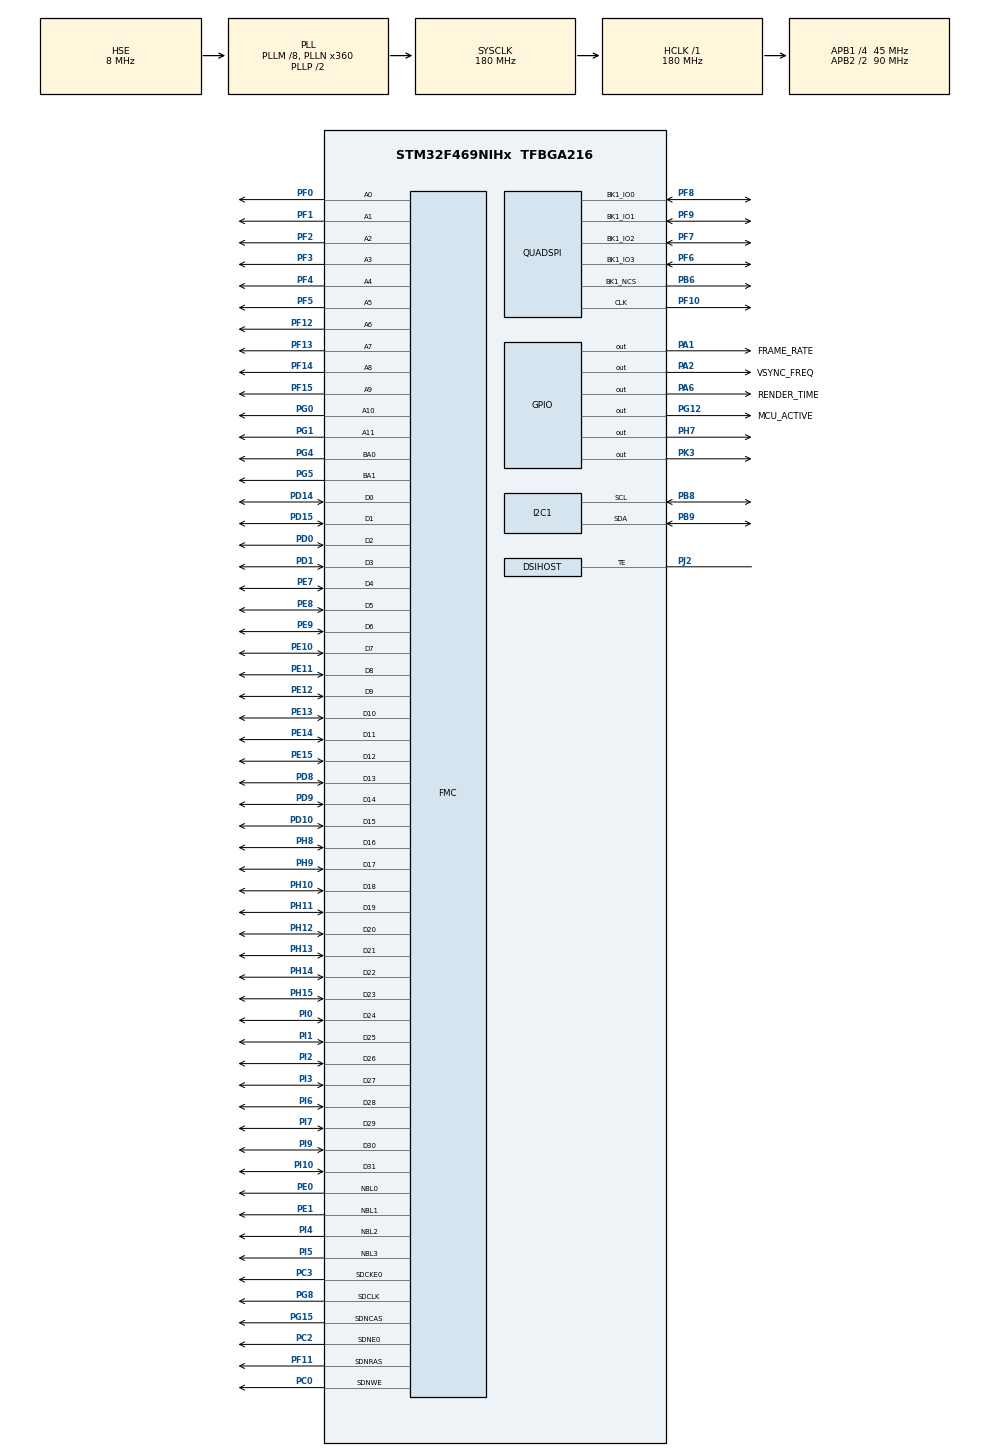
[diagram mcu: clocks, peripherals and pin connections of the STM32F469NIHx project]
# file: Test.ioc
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DMA2D.ColorMode=DMA2D_OUTPUT_ARGB8888
DSIHOST.AcknowledgeRequest=DSI_ACKNOWLEDGE_ENABLE
DSIHOST.AutomaticRefresh=DSI_AR_DISABLE
DSIHOST.CommandSize=200
DSIHOST.LPDcsLongWrite=DSI_LP_DLW_ENABLE
DSIHOST.LPDcsShortReadNoP=DSI_LP_DSR0P_ENABLE
DSIHOST.LPDcsShortWriteNoP=DSI_LP_DSW0P_ENABLE
DSIHOST.LPDcsShortWriteOneP=DSI_LP_DSW1P_ENABLE
DSIHOST.LPGenLongWrite=DSI_LP_GLW_ENABLE
DSIHOST.LPGenShortReadNoP=DSI_LP_GSR0P_ENABLE
DSIHOST.LPGenShortReadOneP=DSI_LP_GSR1P_ENABLE
DSIHOST.LPGenShortReadTwoP=DSI_LP_GSR2P_ENABLE
DSIHOST.LPGenShortWriteNoP=DSI_LP_GSW0P_ENABLE
DSIHOST.LPGenShortWriteOneP=DSI_LP_GSW1P_ENABLE
DSIHOST.LPGenShortWriteTwoP=DSI_LP_GSW2P_ENABLE
DSIHOST.LPMaxReadPacket=DSI_LP_MRDP_ENABLE
DSIHOST.NumberOfLanes=DSI_TWO_DATA_LANES
DSIHOST.TEAcknowledgeRequest=DSI_TE_ACKNOWLEDGE_ENABLE
DSIHOST.TimeoutCkdiv=1
DSIHOST_CKN.Mode=DSIHost_Adapted_TE
DSIHOST_CKN.Signal=DSIHOST_CKN
DSIHOST_CKP.Mode=DSIHost_Adapted_TE
DSIHOST_CKP.Signal=DSIHOST_CKP
DSIHOST_D0N.Mode=DSIHost_Adapted_TE
DSIHOST_D0N.Signal=DSIHOST_D0N
DSIHOST_D0P.Mode=DSIHost_Adapted_TE
DSIHOST_D0P.Signal=DSIHOST_D0P
DSIHOST_D1N.Mode=DSIHost_Adapted_TE
DSIHOST_D1N.Signal=DSIHOST_D1N
DSIHOST_D1P.Mode=DSIHost_Adapted_TE
DSIHOST_D1P.Signal=DSIHOST_D1P
FMC.CASLatency1=FMC_SDRAM_CAS_LATENCY_3
FMC.ExitSelfRefreshDelay1=7
FMC.LoadToActiveDelay1=2
FMC.RCDDelay1=2
FMC.RPDelay1=2
FMC.ReadBurst1=FMC_SDRAM_RBURST_ENABLE
FMC.ReadPipeDelay1=FMC_SDRAM_RPIPE_DELAY_2
FMC.RowCycleDelay1=7
FMC.SelfRefreshTime1=4
FMC.WriteRecoveryTime1=3
FREERTOS.Tasks01=defaultTask,24,128,StartDefaultTask,Default,NULL,Dynamic,NULL,NULL;TouchGFXTask,24,4096,TouchGFX_Task,As external,NULL,Dynamic,NULL,NULL;readAdcTaskName,48,128,readAdcFunction,As external,NULL,Dynamic,NULL,NULL
FREERTOS.configTOTAL_HEAP_SIZE=32768
FREERTOS.configUSE_APPLICATION_TASK_TAG=1
FREERTOS.configUSE_IDLE_HOOK=1
FREERTOS.configUSE_NEWLIB_REENTRANT=1
FREERTOS.configUSE_TRACE_FACILITY=1
I2C1.I2C_Mode=I2C_Fast
LTDC.ActiveW=200
LTDC.Alpha_L0=255
LTDC.FBStartAdress_L0=0xC0000000
LTDC.HBP=1
LTDC.HFP=1
LTDC.HSync=2
LTDC.ImageHeight_L0=480
LTDC.ImageWidth_L0=200
LTDC.Layers=0
LTDC.PixelFormat_L0=LTDC_PIXEL_FORMAT_RGB565
LTDC.VBP=1
LTDC.VFP=1
LTDC.VSync=2
LTDC.WindowX1_L0=200
LTDC.WindowY1_L0=480
Mcu.Family=STM32F4
Mcu.Name=STM32F469NIHx
Mcu.Package=TFBGA216
NVIC.DMA2D_IRQn=true\:5\:0\:true\:false\:true\:false\:true\:true\:true
NVIC.DSI_IRQn=true\:5\:0\:true\:false\:true\:false\:true\:true\:true
NVIC.LTDC_IRQn=true\:5\:0\:true\:false\:true\:false\:true\:true\:true
NVIC.PriorityGroup=NVIC_PRIORITYGROUP_4
NVIC.TIM6_DAC_IRQn=true\:0\:0\:false\:false\:true\:false\:false\:true\:true
NVIC.TimeBase=TIM6_DAC_IRQn
NVIC.TimeBaseIP=TIM6
PA1.GPIO_Label=FRAME_RATE
PA1.GPIO_Speed=GPIO_SPEED_FREQ_VERY_HIGH
PA1.Signal=GPIO_Output
PA2.GPIO_Label=VSYNC_FREQ
PA2.GPIO_Speed=GPIO_SPEED_FREQ_VERY_HIGH
PA2.Signal=GPIO_Output
PA6.GPIO_Label=RENDER_TIME
PA6.GPIO_Speed=GPIO_SPEED_FREQ_VERY_HIGH
PA6.Signal=GPIO_Output
PB6.Mode=Single Bank 1
PB6.Signal=QUADSPI_BK1_NCS
PB8.GPIO_Pu=GPIO_PULLUP
PB8.Mode=I2C
PB8.Signal=I2C1_SCL
PB9.GPIO_Pu=GPIO_PULLUP
PB9.Mode=I2C
PB9.Signal=I2C1_SDA
PC0.Signal=FMC_SDNWE
PC2.Mode=SdramChipSelect1_1
PC2.Signal=FMC_SDNE0
PC3.Mode=SdramChipSelect1_1
PC3.Signal=FMC_SDCKE0
PD0.Signal=FMC_D2_DA2
PD1.Signal=FMC_D3_DA3
PD10.Signal=FMC_D15_DA15
PD14.Signal=FMC_D0_DA0
PD15.Signal=FMC_D1_DA1
PD8.Signal=FMC_D13_DA13
PD9.Signal=FMC_D14_DA14
PE0.Signal=FMC_NBL0
PE1.Signal=FMC_NBL1
PE10.Signal=FMC_D7_DA7
PE11.Signal=FMC_D8_DA8
PE12.Signal=FMC_D9_DA9
PE13.Signal=FMC_D10_DA10
PE14.Signal=FMC_D11_DA11
PE15.Signal=FMC_D12_DA12
PE7.Signal=FMC_D4_DA4
PE8.Signal=FMC_D5_DA5
PE9.Signal=FMC_D6_DA6
PF0.Signal=FMC_A0
PF1.Signal=FMC_A1
PF10.Mode=Single Bank 1
PF10.Signal=QUADSPI_CLK
PF11.Signal=FMC_SDNRAS
PF12.Signal=FMC_A6
PF13.Signal=FMC_A7
PF14.Signal=FMC_A8
PF15.Signal=FMC_A9
PF2.Signal=FMC_A2
PF3.Signal=FMC_A3
PF4.Signal=FMC_A4
PF5.Signal=FMC_A5
PF6.Mode=Single Bank 1
PF6.Signal=QUADSPI_BK1_IO3
PF7.Mode=Single Bank 1
PF7.Signal=QUADSPI_BK1_IO2
PF8.Mode=Single Bank 1
PF8.Signal=QUADSPI_BK1_IO0
PF9.Mode=Single Bank 1
PF9.Signal=QUADSPI_BK1_IO1
PG0.Signal=FMC_A10
PG1.Signal=FMC_A11
PG12.GPIO_Label=MCU_ACTIVE
PG12.GPIO_Speed=GPIO_SPEED_FREQ_VERY_HIGH
PG12.Signal=GPIO_Output
PG15.Signal=FMC_SDNCAS
PG4.Signal=FMC_A14_BA0
PG5.Signal=FMC_A15_BA1
PG8.Signal=FMC_SDCLK
PH0/OSC_IN.Mode=HSE-External-Oscillator
PH0/OSC_IN.Signal=RCC_OSC_IN
PH1/OSC_OUT.Mode=HSE-External-Oscillator
PH1/OSC_OUT.Signal=RCC_OSC_OUT
PH10.Signal=FMC_D18
PH11.Signal=FMC_D19
PH12.Signal=FMC_D20
PH13.Signal=FMC_D21
PH14.Signal=FMC_D22
PH15.Signal=FMC_D23
PH7.GPIO_ModeDefaultOutputPP=GPIO_MODE_OUTPUT_OD
PH7.GPIO_Speed=GPIO_SPEED_FREQ_VERY_HIGH
PH7.PinState=GPIO_PIN_RESET
PH7.Signal=GPIO_Output
PH8.Signal=FMC_D16
PH9.Signal=FMC_D17
PI0.Signal=FMC_D24
PI1.Signal=FMC_D25
PI10.Signal=FMC_D31
PI2.Signal=FMC_D26
PI3.Signal=FMC_D27
PI4.Signal=FMC_NBL2
PI5.Signal=FMC_NBL3
PI6.Signal=FMC_D28
PI7.Signal=FMC_D29
PI9.Signal=FMC_D30
PJ2.Mode=DSIHost_Adapted_TE
PJ2.Signal=DSIHOST_TE
PK3.GPIO_ModeDefaultOutputPP=GPIO_MODE_OUTPUT_OD
PK3.PinState=GPIO_PIN_SET
PK3.Signal=GPIO_Output
ProjectManager.HeapSize=0x1000
ProjectManager.StackSize=0x1000
ProjectManager.TargetToolchain=STM32CubeIDE
QUADSPI.ChipSelectHighTime=QSPI_CS_HIGH_TIME_5_CYCLE
QUADSPI.ClockPrescaler=1
QUADSPI.FlashSize=27
QUADSPI.SampleShifting=QSPI_SAMPLE_SHIFTING_HALFCYCLE
RCC.AHBFreq_Value=180000000
RCC.APB1CLKDivider=RCC_HCLK_DIV4
RCC.APB1Freq_Value=45000000
RCC.APB1TimFreq_Value=90000000
RCC.APB2CLKDivider=RCC_HCLK_DIV2
RCC.APB2Freq_Value=90000000
RCC.APB2TimFreq_Value=180000000
RCC.CortexFreq_Value=180000000
RCC.HCLKFreq_Value=180000000
RCC.HSE_VALUE=8000000
RCC.PLLDSIIDF=DSI_PLL_IN_DIV2
RCC.PLLDSINDIV=125
RCC.PLLM=8
RCC.PLLN=360
RCC.PLLR=6
RCC.PLLSAIN=360
RCC.PLLSAIR=6
RCC.PLLSourceVirtual=RCC_PLLSOURCE_HSE
RCC.SYSCLKFreq_VALUE=180000000
RCC.SYSCLKSource=RCC_SYSCLKSOURCE_PLLCLK
RCC.USBFreq_Value=90000000
RCC.VCOOutputFreq_Value=360000000
SH.FMC_A0.0=FMC_A0,12b-sda1
SH.FMC_A1.0=FMC_A1,12b-sda1
SH.FMC_A10.0=FMC_A10,12b-sda1
SH.FMC_A11.0=FMC_A11,12b-sda1
SH.FMC_A14_BA0.0=FMC_BA0,FourSdramBanks1
SH.FMC_A15_BA1.0=FMC_BA1,FourSdramBanks1
SH.FMC_A2.0=FMC_A2,12b-sda1
SH.FMC_A3.0=FMC_A3,12b-sda1
SH.FMC_A4.0=FMC_A4,12b-sda1
SH.FMC_A5.0=FMC_A5,12b-sda1
SH.FMC_A6.0=FMC_A6,12b-sda1
SH.FMC_A7.0=FMC_A7,12b-sda1
SH.FMC_A8.0=FMC_A8,12b-sda1
SH.FMC_A9.0=FMC_A9,12b-sda1
SH.FMC_D0_DA0.0=FMC_D0,sd-32b-d1
SH.FMC_D10_DA10.0=FMC_D10,sd-32b-d1
SH.FMC_D11_DA11.0=FMC_D11,sd-32b-d1
SH.FMC_D12_DA12.0=FMC_D12,sd-32b-d1
SH.FMC_D13_DA13.0=FMC_D13,sd-32b-d1
SH.FMC_D14_DA14.0=FMC_D14,sd-32b-d1
SH.FMC_D15_DA15.0=FMC_D15,sd-32b-d1
SH.FMC_D16.0=FMC_D16,sd-32b-d1
SH.FMC_D17.0=FMC_D17,sd-32b-d1
SH.FMC_D18.0=FMC_D18,sd-32b-d1
SH.FMC_D19.0=FMC_D19,sd-32b-d1
SH.FMC_D1_DA1.0=FMC_D1,sd-32b-d1
SH.FMC_D20.0=FMC_D20,sd-32b-d1
SH.FMC_D21.0=FMC_D21,sd-32b-d1
SH.FMC_D22.0=FMC_D22,sd-32b-d1
SH.FMC_D23.0=FMC_D23,sd-32b-d1
SH.FMC_D24.0=FMC_D24,sd-32b-d1
SH.FMC_D25.0=FMC_D25,sd-32b-d1
SH.FMC_D26.0=FMC_D26,sd-32b-d1
SH.FMC_D27.0=FMC_D27,sd-32b-d1
SH.FMC_D28.0=FMC_D28,sd-32b-d1
SH.FMC_D29.0=FMC_D29,sd-32b-d1
SH.FMC_D2_DA2.0=FMC_D2,sd-32b-d1
SH.FMC_D30.0=FMC_D30,sd-32b-d1
SH.FMC_D31.0=FMC_D31,sd-32b-d1
SH.FMC_D3_DA3.0=FMC_D3,sd-32b-d1
SH.FMC_D4_DA4.0=FMC_D4,sd-32b-d1
SH.FMC_D5_DA5.0=FMC_D5,sd-32b-d1
SH.FMC_D6_DA6.0=FMC_D6,sd-32b-d1
SH.FMC_D7_DA7.0=FMC_D7,sd-32b-d1
SH.FMC_D8_DA8.0=FMC_D8,sd-32b-d1
SH.FMC_D9_DA9.0=FMC_D9,sd-32b-d1
SH.FMC_NBL0.0=FMC_NBL0,Sd4ByteEnable1
SH.FMC_NBL1.0=FMC_NBL1,Sd4ByteEnable1
SH.FMC_NBL2.0=FMC_NBL2,Sd4ByteEnable1
SH.FMC_NBL3.0=FMC_NBL3,Sd4ByteEnable1
SH.FMC_SDCLK.0=FMC_SDCLK,12b-sda1
SH.FMC_SDNCAS.0=FMC_SDNCAS,12b-sda1
SH.FMC_SDNRAS.0=FMC_SDNRAS,12b-sda1
SH.FMC_SDNWE.0=FMC_SDNWE,12b-sda1
STMicroelectronics.X-CUBE-TOUCHGFX.4.21.1_IsPackSelfContextualization=true
VP_CRC_VS_CRC.Mode=CRC_Activate
VP_DMA2D_VS_DMA2D.Mode=DMA2D_Activate
VP_FREERTOS_VS_CMSIS_V2.Mode=CMSIS_V2
VP_LTDC_DSIMode.Mode=RGB565
VP_SYS_VS_tim6.Mode=TIM6
board=custom

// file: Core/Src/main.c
/* USER CODE BEGIN Header */
/**
 ******************************************************************************
 * @file           : main.c
 * @brief          : Main program body
 ******************************************************************************
 * @attention
 *
 * Copyright (c) 2023 STMicroelectronics.
 * All rights reserved.
 *
 * This software is licensed under terms that can be found in the LICENSE file
 * in the root directory of this software component.
 * If no LICENSE file comes with this software, it is provided AS-IS.
 *
 ******************************************************************************
 */
/* USER CODE END Header */
#include "main.h"
#include "cmsis_os.h"
#include "crc.h"
#include "dma2d.h"
#include "dsihost.h"
#include "i2c.h"
#include "ltdc.h"
#include "quadspi.h"
#include "gpio.h"
#include "fmc.h"

/* USER CODE BEGIN Includes */
#ifndef USE_FULL_LL_DRIVER
#define USE_FULL_LL_DRIVER
#endif

#ifdef USE_SEGGER_SYSVIEW
#include "SEGGER_SYSVIEW.h"
#endif

#include "u_adc.h"
#include "u_gpio.h"
#include "u_pwm.h"
#include "u_rcc.h"
#include "u_firmwareDefination.h"
#include "u_appMain.h"

#include "u_lfc_firmware.h"

/* USER CODE END Includes */

void SystemClock_Config(void);
void MX_FREERTOS_Init(void);

/* USER CODE BEGIN 0 */
extern uint32_t _sitouchgfxccmram;
extern uint32_t _stouchgfxccmram;
extern uint32_t _etouchgfxccmram;
void initCcmRam()
{
  uint32_t sizeOfDataInCcmRam = &_etouchgfxccmram - &_stouchgfxccmram;
  uint8_t *l_des_ptr = (uint8_t *)&_stouchgfxccmram;
  uint8_t *l_src_ptr = (uint8_t *)&_sitouchgfxccmram;
  for (size_t i = 0; i < sizeOfDataInCcmRam; i++)
  {
    *l_des_ptr = *l_src_ptr;
    l_des_ptr++;
    l_src_ptr++;
  }
}
/* USER CODE END 0 */

int main(void)
{

  /* MCU Configuration--------------------------------------------------------*/

  /* Reset of all peripherals, Initializes the Flash interface and the Systick. */
  HAL_Init();

  /* Configure the system clock */
  SystemClock_Config();

  /* USER CODE BEGIN SysInit */
  // NVIC_SetPriorityGrouping( 0 );
  /* USER CODE END SysInit */

  /* Initialize all configured peripherals */
  MX_GPIO_Init();
  MX_CRC_Init();
  MX_DMA2D_Init();
  MX_DSIHOST_DSI_Init();
  MX_FMC_Init();
  MX_LTDC_Init();
  MX_QUADSPI_Init();
  MX_I2C1_Init();
  /* USER CODE BEGIN 2 */
#ifdef USE_SEGGER_SYSVIEW
 NVIC_SetPriorityGrouping( 0 );
 SEGGER_SYSVIEW_Conf();
 SEGGER_SYSVIEW_Start();
#endif /* USE_SEGGER_SYSVIEW */

  u_gpio_OnboardInit_LED();
  u_pwm_init();
  // u_adc_Init();
  u_adc_initSingleConversion();
  u_gpio_Init_DigitalOutput();
  u_gpio_Init_externalInterrupt();
  LL_ADC_Enable(ADC1);
  HAL_Delay(10);
  u_appMainCreate();
  U_LFC_GPIO_Init();
  /* USER CODE END 2 */

  /* Init scheduler */
  osKernelInitialize(); /* Call init function for freertos objects (in freertos.c) */
  MX_FREERTOS_Init();

  /* Start scheduler */

 //  osKernelStart();
  /* We should never get here as control is now taken by the scheduler */
  /* Infinite loop */
  while (1)
  {
	  u_gpio_outputSet(GPIOC	, 5);
  }
}

void SystemClock_Config(void)
{
  RCC_OscInitTypeDef RCC_OscInitStruct = {0};
  RCC_ClkInitTypeDef RCC_ClkInitStruct = {0};

  /** Configure the main internal regulator output voltage
   */
  __HAL_RCC_PWR_CLK_ENABLE();
  __HAL_PWR_VOLTAGESCALING_CONFIG(PWR_REGULATOR_VOLTAGE_SCALE1);

  /** Initializes the RCC Oscillators according to the specified parameters
   * in the RCC_OscInitTypeDef structure.
   */
  RCC_OscInitStruct.OscillatorType = RCC_OSCILLATORTYPE_HSE;
  RCC_OscInitStruct.HSEState = RCC_HSE_ON;
  RCC_OscInitStruct.PLL.PLLState = RCC_PLL_ON;
  RCC_OscInitStruct.PLL.PLLSource = RCC_PLLSOURCE_HSE;
  RCC_OscInitStruct.PLL.PLLM = 8;
  RCC_OscInitStruct.PLL.PLLN = 360;
  RCC_OscInitStruct.PLL.PLLP = RCC_PLLP_DIV2;
  RCC_OscInitStruct.PLL.PLLQ = 4;
  RCC_OscInitStruct.PLL.PLLR = 6;
  if (HAL_RCC_OscConfig(&RCC_OscInitStruct) != HAL_OK)
  {
    Error_Handler();
  }

  /** Activate the Over-Drive mode
   */
  if (HAL_PWREx_EnableOverDrive() != HAL_OK)
  {
    Error_Handler();
  }

  /** Initializes the CPU, AHB and APB buses clocks
   */
  RCC_ClkInitStruct.ClockType = RCC_CLOCKTYPE_HCLK | RCC_CLOCKTYPE_SYSCLK | RCC_CLOCKTYPE_PCLK1 | RCC_CLOCKTYPE_PCLK2;
  RCC_ClkInitStruct.SYSCLKSource = RCC_SYSCLKSOURCE_PLLCLK;
  RCC_ClkInitStruct.AHBCLKDivider = RCC_SYSCLK_DIV1;
  RCC_ClkInitStruct.APB1CLKDivider = RCC_HCLK_DIV4;
  RCC_ClkInitStruct.APB2CLKDivider = RCC_HCLK_DIV2;

  if (HAL_RCC_ClockConfig(&RCC_ClkInitStruct, FLASH_LATENCY_5) != HAL_OK)
  {
    Error_Handler();
  }
}

/* USER CODE BEGIN 4 */
void TouchGFX_Task(void *argument)
{
  while (1)
  {
  }
}

/* USER CODE END 4 */

void HAL_TIM_PeriodElapsedCallback(TIM_HandleTypeDef *htim)
{
  if (htim->Instance == TIM6)
  {
    HAL_IncTick();
  }
}

void Error_Handler(void)
{
  __disable_irq();
  while (1)
  {
  }
}
